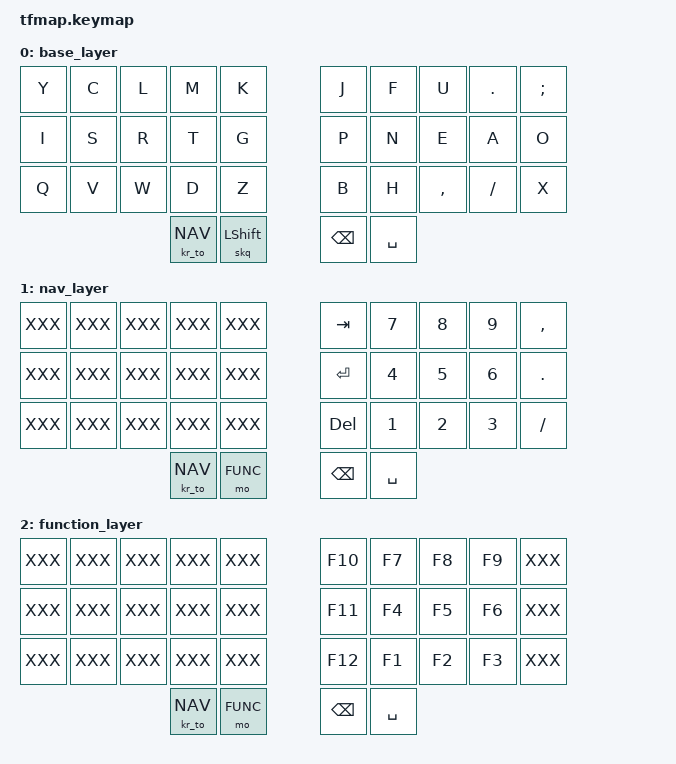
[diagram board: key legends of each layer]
/*
 * Copyright (c) 2020 The ZMK Contributors
 *
 * SPDX-License-Identifier: MIT
 */

#include <behaviors.dtsi>
#include <dt-bindings/zmk/keys.h>
#include <dt-bindings/zmk/bt.h>
#include "tfmap.h"


&sk {
  release-after-ms = <STICKY_KEY_TIMEOUT>;
};

&caps_word {
  continue-list = <UNDERSCORE MINUS BACKSPACE>;
};


/ {

    combos {
        //#include "combos.dtsi"
    };

    macros {
        //#include "macros.dtsi"
    };

    behaviors {
        skq: sticky_key_quick_release {
            compatible = "zmk,behavior-sticky-key";
            label = "STICKY_KEY_QUICK_RELEASE";
            #binding-cells = <1>;
            bindings = <&kp>;
            release-after-ms = <STICKY_KEY_TIMEOUT>;
            quick-release;
        };
        kr_to: key_repeat_to_layer {
            compatible = "zmk,behavior-hold-tap";
            label = "KEY_REPEAT_TO_LAYER";
            #binding-cells = <2>;
            bindings = <&key_repeat>, <&mo>;
        };
     //   if_shft: if_shift {
     //       compatible = "zmk,behavior-mod-morph";
     //       label = "IF_SHIFT";
     //       #binding-cells = <0>;
     //       bindings = <&kp BKSP>, <&macro_dw 0>;
     //       mods = <(MOD_LSFT|MOD_RSFT)>;
     //   };
    //    dw_mod: delete_word_mod {
    //        compatible = "zmk,behavior-hold-tap";
    //        label = "DELETE_WORD_MOD";
    //        #binding-cells = <2>;
    //        bindings = <&kp>, <&macro_dw>;
    //    };

    };

    keymap {
        compatible = "zmk,keymap";

        base_layer {
            bindings = <
// ╭─────────────┬─────────────┬─────────────┬─────────────┬─────────────╮   ╭─────────────┬─────────────┬─────────────┬─────────────┬─────────────╮
        &kp Y         &kp C         &kp L         &kp M         &kp K             &kp J         &kp F         &kp U         &kp DOT       &kp SEMICOLON
// ├─────────────┼─────────────┼─────────────┼─────────────┼─────────────┤   ├─────────────┼─────────────┼─────────────┼─────────────┼─────────────┤
        &kp I         &kp S         &kp R         &kp T         &kp G             &kp P         &kp N         &kp E         &kp A         &kp O
// ├─────────────┼─────────────┼─────────────┼─────────────┼─────────────┤   ├─────────────┼─────────────┼─────────────┼─────────────┼─────────────┤
        &kp Q         &kp V         &kp W         &kp D         &kp Z             &kp B         &kp H         &kp COMMA    &kp SLASH      &kp X
// ╰─────────────┴─────────────┴─────────────┼─────────────┼─────────────┤   ├─────────────┼─────────────┼─────────────┴─────────────┴─────────────╯
                                                &kr_to NAV      &skq LSHIFT       &kp BKSP &kp SPACE
//                                           ╰─────────────┴─────────────╯   ╰─────────────┴─────────────╯
                        >;
        };

        nav_layer {
            bindings = <
// ╭─────────────┬─────────────┬─────────────┬─────────────┬─────────────╮   ╭─────────────┬─────────────┬─────────────┬─────────────┬─────────────╮
        XXX           XXX           XXX           XXX           XXX               &kp TAB       &kp N7         &kp N8        &kp N9        &kp COMMA
// ├─────────────┼─────────────┼─────────────┼─────────────┼─────────────┤   ├─────────────┼─────────────┼─────────────┼─────────────┼─────────────┤
        XXX           XXX           XXX           XXX           XXX               &kp ENTER     &kp N4         &kp N5        &kp N6        &kp DOT
// ├─────────────┼─────────────┼─────────────┼─────────────┼─────────────┤   ├─────────────┼─────────────┼─────────────┼─────────────┼─────────────┤
        XXX           XXX           XXX           XXX           XXX               &kp DELETE    &kp N1         &kp N2        &kp N3        &kp SLASH
// ╰─────────────┴─────────────┴─────────────┼─────────────┼─────────────┤   ├─────────────┼─────────────┼─────────────┴─────────────┴─────────────╯
                                                &kr_to NAV      &mo FUNC          &kp BKSP      &kp SPACE
//                                           ╰─────────────┴─────────────╯   ╰─────────────┴─────────────╯
                        >;
		};

        function_layer {
            bindings = <
// ╭─────────────┬─────────────┬─────────────┬─────────────┬─────────────╮   ╭─────────────┬─────────────┬─────────────┬─────────────┬─────────────╮
        XXX           XXX           XXX           XXX           XXX               &kp F10       &kp F7         &kp F8        &kp F9        XXX
// ├─────────────┼─────────────┼─────────────┼─────────────┼─────────────┤   ├─────────────┼─────────────┼─────────────┼─────────────┼─────────────┤
        XXX           XXX           XXX           XXX           XXX               &kp F11       &kp F4         &kp F5        &kp F6        XXX
// ├─────────────┼─────────────┼─────────────┼─────────────┼─────────────┤   ├─────────────┼─────────────┼─────────────┼─────────────┼─────────────┤
        XXX           XXX           XXX           XXX           XXX               &kp F12       &kp F1         &kp F2        &kp F3        XXX
// ╰─────────────┴─────────────┴─────────────┼─────────────┼─────────────┤   ├─────────────┼─────────────┼─────────────┴─────────────┴─────────────╯
                                                &kr_to NAV      &mo FUNC          &kp BKSP      &kp SPACE
//                                           ╰─────────────┴─────────────╯   ╰─────────────┴─────────────╯
                      >;
		};
	};
};
